# RZT2L register map
Vendor: Renesas Electronics Corporation; Series: RZT; File version: 1.20.00
CPU: other r0p0, little endian, MPU, no FPU, VTOR, 4 interrupt priority bits, 624 interrupts
Registers are 32-bit, read-write, reset 0x0 unless marked. A register's access mark holds for its fields unless they carry their own. Offsets are from the block's base; [hi:lo] are bit positions; {n}, {i} and the like mark numbered series; 'fields as' and 'values as' point back to an identical list.

## GMAC — Ethernet MAC
Base 0x80100000
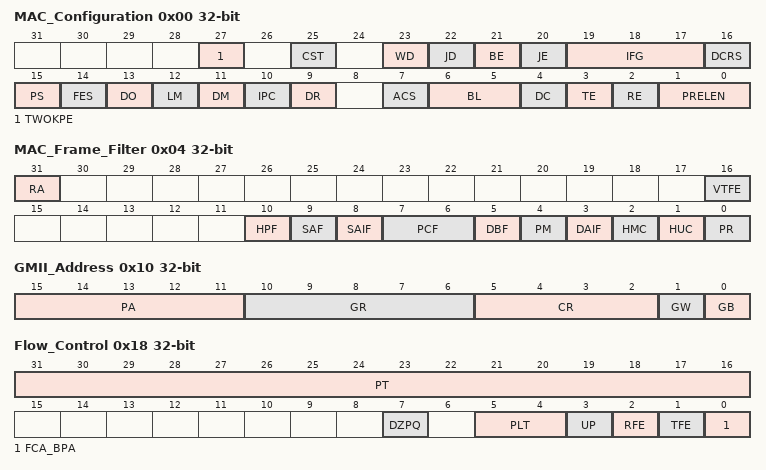
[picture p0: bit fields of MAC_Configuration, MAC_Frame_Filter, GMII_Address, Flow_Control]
0x00 MAC_Configuration
  [27] TWOKPE — IEEE 802.3 as Support for 2 K Packets
  [25] CST — CRC Stripping for Type Frames
  [23] WD — Watchdog Disable
  [22] JD — Jabber Disable
  [21] BE — Frame Burst Enable
  [20] JE — Jumbo Frame Enable
  [19:17] IFG — Inter-Frame Gap
  [16] DCRS — Disable Carrier Sense During Transmission
  [15] PS — Port Select
    0=For 1000 Mbps operations; 1=For 10 or 100 Mbps operations
  [14] FES — Speed
    0=10 Mbps; 1=100 Mbps
  [13] DO — Disable Receive Own
  [12] LM — Loopback Mode
  [11] DM — Duplex Mode
  [10] IPC — Checksum Offload
  [9] DR — Disable Retry
  [7] ACS — Automatic Pad or CRC Stripping
  [6:5] BL — Back-Off Limit
    0=k = min (n, 10); 1=k = min (n, 8); 2=k = min (n, 4); 3=k = min (n, 1)
  [4] DC — Deferral Check
  [3] TE — Transmitter Enable
  [2] RE — Receiver Enable
  [1:0] PRELEN — Preamble Length for Transmit Frames
    0=7 bytes of preamble; 1=5 bytes of preamble; 2=3 bytes of preamble
0x04 MAC_Frame_Filter
  [31] RA — Receive All
  [16] VTFE — VLAN Tag Filter Enable
  [10] HPF — Hash or Perfect Filter
  [9] SAF — Source Address Filter Enable
  [8] SAIF — SA Inverse Filtering
  [7:6] PCF — Pass Control Frames
    0=GMAC filters all control frames from reaching the application; 1=GMAC forwards all control frames except PAUSE control frames to application even if they fail the Address filter; 2=GMAC forwards all control frames to application even if they fail the Address Filter; 3=GMAC forwards control frames that pass the Address Filter
  [5] DBF — Disable Broadcast Frames
  [4] PM — Pass All Multicast
  [3] DAIF — DA Inverse Filtering
  [2] HMC — Hash Multicast
  [1] HUC — Hash Unicast
  [0] PR — Promiscuous Mode
0x10 GMII_Address
  [15:11] PA — Physical Layer Address
  [10:6] GR — GMII Register
  [5:2] CR — CSR Clock Range
    0=The frequency of the CSR clock is 60-100 MHz, and the MDC clock is CSR clock/42; 1=The frequency of the CSR clock is 100-150 MHz, and the MDC clock is CSR clock/62; 2=The frequency of the CSR clock is 20-35 MHz, and the MDC clock is CSR clock/16; 3=The frequency of the CSR clock is 35-60 MHz, and the MDC clock is CSR clock/26; 4=The frequency of the CSR clock is 150-250 MHz, and the MDC clock is CSR clock/102; 5=The frequency of the CSR clock is 250-300 MHz, and the MDC clock is CSR clock/124
  [1] GW — GMII Write
  [0] GB — GMII Busy
0x14 GMII_Data (reset mask 0xFE00)
  [15:0] GD — GMII Data
0x18 Flow_Control
  [31:16] PT — Pause Time
  [7] DZPQ — Disable Zero-Quanta Pause
  [5:4] PLT — Pause Low Threshold
    0=The threshold is Pause time minus 4 slot times (PT - 4 slot times); 1=The threshold is Pause time minus 28 slot times (PT - 28 slot times); 2=The threshold is Pause time minus 144 slot times (PT - 144 slot times); 3=The threshold is Pause time minus 256 slot times (PT - 256 slot times)
  [3] UP — Unicast Pause Frame Detect
  [2] RFE — Receive Flow Control Enable
  [1] TFE — Transmit Flow Control Enable
  [0] FCA_BPA — Flow Control Busy or Backpressure Activate
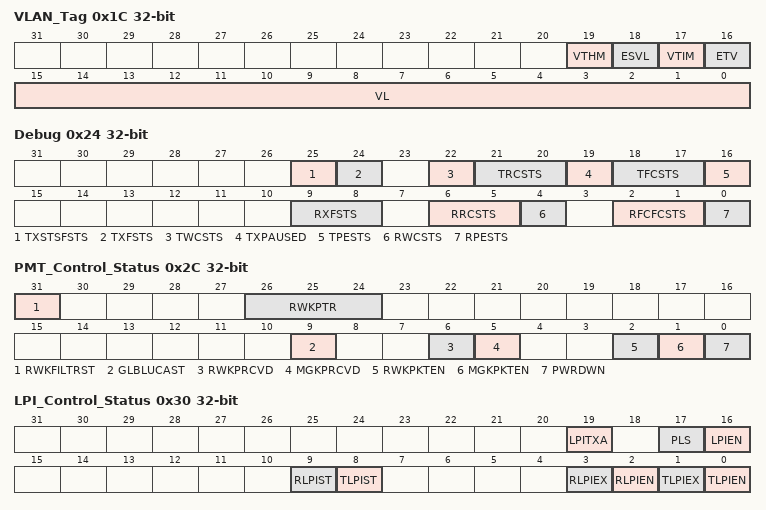
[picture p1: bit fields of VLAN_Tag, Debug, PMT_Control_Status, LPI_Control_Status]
0x1C VLAN_Tag
  [19] VTHM — VLAN Tag Hash Table Match Enable
  [18] ESVL — Enable S-VLAN
  [17] VTIM — VLAN Tag Inverse Match Enable
  [16] ETV — Enable 12-Bit VLAN Tag Comparison
  [15:0] VL — VLAN Tag Identifier for Receive Frames
0x20 Version ro reset 0x3137
  [15:0] VER — Version (GMAC: 0x3137)
0x24 Debug ro
  [25] TXSTSFSTS — MTL TX Status FIFO Full Status
  [24] TXFSTS — MTL TX FIFO Not Empty Status
  [22] TWCSTS — MTL TX FIFO Write Controller Active Status
  [21:20] TRCSTS — MTL TX FIFO Read Controller Status
    0=IDLE state; 1=READ state (transferring data to GMAC transmitter); 2=Waiting for TX status from GMAC transmitter; 3=Writing the received TX status or flushing the TX FIFO
  [19] TXPAUSED — GMAC transmitter in PAUSE
  [18:17] TFCSTS — GMAC Transmit Frame Controller Status
    0=IDLE state; 1=Waiting for status of previous frame, or IFG, or backoff period to be over; 2=Generating and transmitting a Pause control frame (in the full-duplex mode); 3=Transferring input frame for transmission
  [16] TPESTS — GMAC GMII or MII Transmit Protocol Engine Status
  [9:8] RXFSTS — MTL RX FIFO Fill-level Status
    0=RX FIFO Empty; 1=RX FIFO fill level is below the flow-control deactivate threshold; 2=RX FIFO fill level is above the flow-control activate threshold; 3=RX FIFO Full
  [6:5] RRCSTS — MTL RX FIFO Read Controller State
    0=IDLE state; 1=Reading frame data; 2=Reading frame status (or timestamp); 3=Flushing the frame data and status
  [4] RWCSTS — MTL RX FIFO Write Controller Active Status
  [2:1] RFCFCSTS — GMAC Receive Frame Controller FIFO Status
  [0] RPESTS — GMAC GMII or MII Receive Protocol Engine Status
0x28 Remote_Wake_Up_Frame_Filter
  [31:0] WKUPFRMFTR — Remote Wake-Up Frame Filter
0x2C PMT_Control_Status — PMT Control and Status Register
  [31] RWKFILTRST — Wake-Up Frame Filter Register Pointer Reset
  [26:24] RWKPTR ro — Remote Wake-Up FIFO Pointer
  [9] GLBLUCAST — Global Unicast
  [6] RWKPRCVD ro — Wake-Up Frame Received
  [5] MGKPRCVD ro — Magic Packet Received
  [2] RWKPKTEN — Wake-Up Frame Enable
  [1] MGKPKTEN — Magic Packet Enable
  [0] PWRDWN — Power Down
0x30 LPI_Control_Status — LPI Control and Status Register
  [19] LPITXA — LPI TX Automate
  [17] PLS — PHY Link Status
  [16] LPIEN — LPI Enable
  [9] RLPIST ro — Receive LPI State
  [8] TLPIST ro — Transmit LPI State
  [3] RLPIEX ro — Receive LPI Exit
  [2] RLPIEN ro — Receive LPI Entry
  [1] TLPIEX ro — Transmit LPI Exit
  [0] TLPIEN ro — Transmit LPI Entry
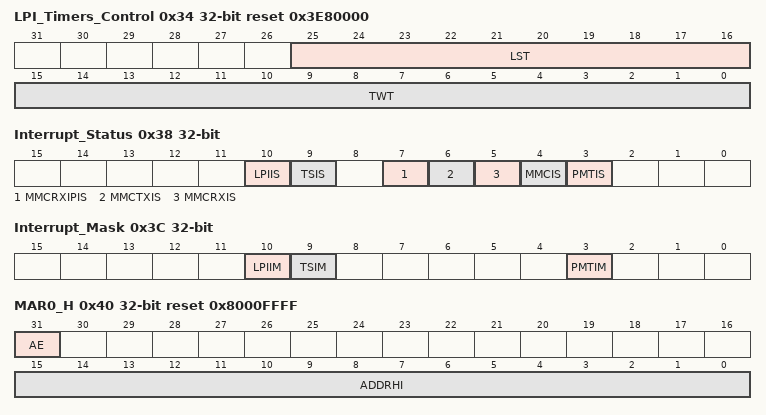
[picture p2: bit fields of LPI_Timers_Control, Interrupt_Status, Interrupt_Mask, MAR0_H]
0x34 LPI_Timers_Control reset 0x3E80000
  [25:16] LST — LPI LS Timer
  [15:0] TWT — LPI TW Timer
0x38 Interrupt_Status ro
  [10] LPIIS — LPI Interrupt Status
  [9] TSIS — Timestamp Interrupt Status
  [7] MMCRXIPIS — MMC Receive Checksum Offload Interrupt Status
  [6] MMCTXIS — MMC Transmit Interrupt Status
  [5] MMCRXIS — MMC Receive Interrupt Status
  [4] MMCIS — MMC Interrupt Status
  [3] PMTIS — PMT Interrupt Status
0x3C Interrupt_Mask reset not defined
  [10] LPIIM — LPI Interrupt Mask
  [9] TSIM — Timestamp Interrupt Mask
  [3] PMTIM — PMT Interrupt Mask
0x40 MAR0_H reset 0x8000FFFF — MAC Address 0 High Register
  [31] AE ro — Address Enable
  [15:0] ADDRHI — MAC Address0[47:32]
0x44 MAR0_L reset 0xFFFFFFFF — MAC Address 0 Low Register
  [31:0] ADDRLO — MAC Address0[31:0]
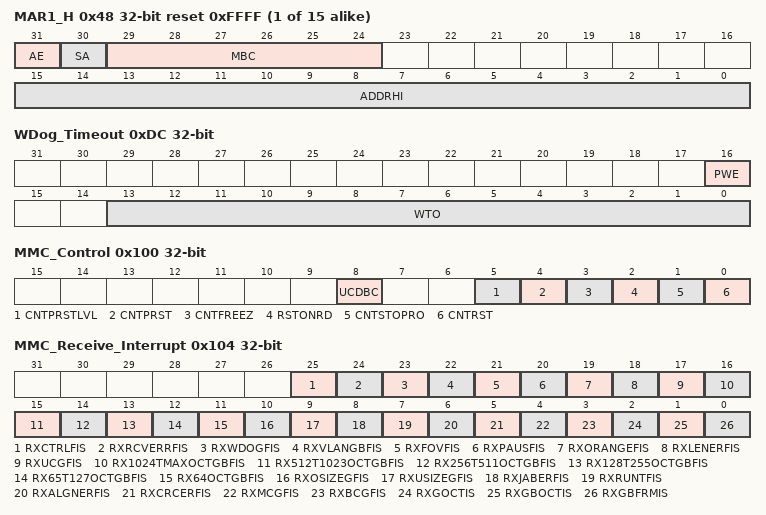
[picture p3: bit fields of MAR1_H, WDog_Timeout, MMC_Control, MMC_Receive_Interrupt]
{0x40+8i} MAR{i}_H (i=1..15) reset 0xFFFF — MAC ADDRESS High Register
  [31] AE — Address Enable
  [30] SA — Source Address
  [29:24] MBC — Mask Byte Control
  [15:0] ADDRHI — MAC Address n[47:32]
{0x44+8i} MAR{i}_L (i=1..15) reset 0xFFFFFFFF — MAC ADDRESS Low Register
  [31:0] ADDRLO — MAC Address n[31:0]
0xDC WDog_Timeout — Watchdog Timeout Register
  [16] PWE — Programmable Watchdog Enable
  [13:0] WTO — Watchdog Timeout
0x100 MMC_Control
  [8] UCDBC — Update MMC Counters for Dropped Broadcast Frames
  [5] CNTPRSTLVL — Full-Half Preset
  [4] CNTPRST — Counters Preset
  [3] CNTFREEZ — MMC Counter Freeze
  [2] RSTONRD — Reset on Read
  [1] CNTSTOPRO — Counters Stop Rollover
  [0] CNTRST — Counters Reset
0x104 MMC_Receive_Interrupt ro
  [25] RXCTRLFIS — MMC Receive Control Frame Counter Interrupt Status
  [24] RXRCVERRFIS — MMC Receive Error Frame Counter Interrupt Status
  [23] RXWDOGFIS — MMC Receive Watchdog Error Frame Counter Interrupt Status
  [22] RXVLANGBFIS — MMC Receive VLAN Good Bad Frame Counter Interrupt Status
  [21] RXFOVFIS — MMC Receive FIFO Overflow Frame Counter Interrupt Status
  [20] RXPAUSFIS — MMC Receive Pause Frame Counter Interrupt Status
  [19] RXORANGEFIS — MMC Receive Out Of Range Error Frame Counter Interrupt Status
  [18] RXLENERFIS — MMC Receive Length Error Frame Counter Interrupt Status
  [17] RXUCGFIS — MMC Receive Unicast Good Frame Counter Interrupt Status
  [16] RX1024TMAXOCTGBFIS — MMC Receive 1024 to Maximum Octet Good Bad Frame Counter Interrupt Status
  [15] RX512T1023OCTGBFIS — MMC Receive 512 to 1023 Octet Good Bad Frame Counter Interrupt Status
  [14] RX256T511OCTGBFIS — MMC Receive 256 to 511 Octet Good Bad Frame Counter Interrupt Status
  [13] RX128T255OCTGBFIS — MMC Receive 128 to 255 Octet Good Bad Frame Counter Interrupt Status
  [12] RX65T127OCTGBFIS — MMC Receive 65 to 127 Octet Good Bad Frame Counter Interrupt Status
  [11] RX64OCTGBFIS — MMC Receive 64 Octet Good Bad Frame Counter Interrupt Status
  [10] RXOSIZEGFIS — MMC Receive Oversize Good Frame Counter Interrupt Status
  [9] RXUSIZEGFIS — MMC Receive Undersize Good Frame Counter Interrupt Status
  [8] RXJABERFIS — MMC Receive Jabber Error Frame Counter Interrupt Status
  [7] RXRUNTFIS — MMC Receive Runt Frame Counter Interrupt Status
  [6] RXALGNERFIS — MMC Receive Alignment Error Frame Counter Interrupt Status
  [5] RXCRCERFIS — MMC Receive CRC Error Frame Counter Interrupt Status
  [4] RXMCGFIS — MMC Receive Multicast Good Frame Counter Interrupt Status
  [3] RXBCGFIS — MMC Receive Broadcast Good Frame Counter Interrupt Status
  [2] RXGOCTIS — MMC Receive Good Octet Counter Interrupt Status
  [1] RXGBOCTIS — MMC Receive Good Bad Octet Counter Interrupt Status
  [0] RXGBFRMIS — MMC Receive Good Bad Frame Counter Interrupt Status
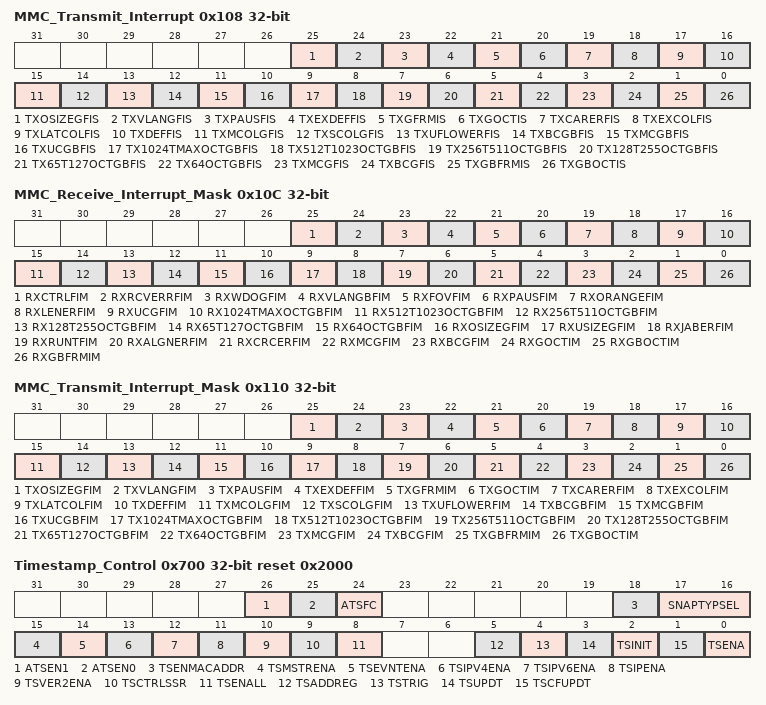
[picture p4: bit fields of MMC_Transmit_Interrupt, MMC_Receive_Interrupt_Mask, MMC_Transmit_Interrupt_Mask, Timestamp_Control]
0x108 MMC_Transmit_Interrupt ro
  [25] TXOSIZEGFIS — MMC Transmit Oversize Good Frame Counter Interrupt Status
  [24] TXVLANGFIS — MMC Transmit VLAN Good Frame Counter Interrupt Status
  [23] TXPAUSFIS — MMC Transmit Pause Frame Counter Interrupt Status
  [22] TXEXDEFFIS — MMC Transmit Excessive Deferral Frame Counter Interrupt Status
  [21] TXGFRMIS — MMC Transmit Good Frame Counter Interrupt Status
  [20] TXGOCTIS — MMC Transmit Good Octet Counter Interrupt Status
  [19] TXCARERFIS — MMC Transmit Carrier Error Frame Counter Interrupt Status
  [18] TXEXCOLFIS — MMC Transmit Excessive Collision Frame Counter Interrupt Status
  [17] TXLATCOLFIS — MMC Transmit Late Collision Frame Counter Interrupt Status
  [16] TXDEFFIS — MMC Transmit Deferred Frame Counter Interrupt Status
  [15] TXMCOLGFIS — MMC Transmit Multiple Collision Good Frame Counter Interrupt Status
  [14] TXSCOLGFIS — MMC Transmit Single Collision Good Frame Counter Interrupt Status
  [13] TXUFLOWERFIS — MMC Transmit Underflow Error Frame Counter Interrupt Status
  [12] TXBCGBFIS — MMC Transmit Broadcast Good Bad Frame Counter Interrupt Status
  [11] TXMCGBFIS — MMC Transmit Multicast Good Bad Frame Counter Interrupt Status
  [10] TXUCGBFIS — MMC Transmit Unicast Good Bad Frame Counter Interrupt Status
  [9] TX1024TMAXOCTGBFIS — MMC Transmit 1024 to Maximum Octet Good Bad Frame Counter Interrupt Status
  [8] TX512T1023OCTGBFIS — MMC Transmit 512 to 1023 Octet Good Bad Frame Counter Interrupt Status
  [7] TX256T511OCTGBFIS — MMC Transmit 256 to 511 Octet Good Bad Frame Counter Interrupt Status
  [6] TX128T255OCTGBFIS — MMC Transmit 128 to 255 Octet Good Bad Frame Counter Interrupt Status
  [5] TX65T127OCTGBFIS — MMC Transmit 65 to 127 Octet Good Bad Frame Counter Interrupt Status
  [4] TX64OCTGBFIS — MMC Transmit 64 Octet Good Bad Frame Counter Interrupt Status
  [3] TXMCGFIS — MMC Transmit Multicast Good Frame Counter Interrupt Status
  [2] TXBCGFIS — MMC Transmit Broadcast Good Frame Counter Interrupt Status
  [1] TXGBFRMIS — MMC Transmit Good Bad Frame Counter Interrupt Status
  [0] TXGBOCTIS — MMC Transmit Good Bad Octet Counter Interrupt Status
0x10C MMC_Receive_Interrupt_Mask
  [25] RXCTRLFIM — MMC Receive Control Frame Counter Interrupt Mask
  [24] RXRCVERRFIM — MMC Receive Error Frame Counter Interrupt Mask
  [23] RXWDOGFIM — MMC Receive Watchdog Error Frame Counter Interrupt Mask
  [22] RXVLANGBFIM — MMC Receive VLAN Good Bad Frame Counter Interrupt Mask
  [21] RXFOVFIM — MMC Receive FIFO Overflow Frame Counter Interrupt Mask
  [20] RXPAUSFIM — MMC Receive Pause Frame Counter Interrupt Mask
  [19] RXORANGEFIM — MMC Receive Out Of Range Error Frame Counter Interrupt Mask
  [18] RXLENERFIM — MMC Receive Length Error Frame Counter Interrupt Mask
  [17] RXUCGFIM — MMC Receive Unicast Good Frame Counter Interrupt Mask
  [16] RX1024TMAXOCTGBFIM — MMC Receive 1024 to Maximum Octet Good Bad Frame Counter Interrupt Mask
  [15] RX512T1023OCTGBFIM — MMC Receive 512 to 1023 Octet Good Bad Frame Counter Interrupt Mask
  [14] RX256T511OCTGBFIM — MMC Receive 256 to 511 Octet Good Bad Frame Counter Interrupt Mask
  [13] RX128T255OCTGBFIM — MMC Receive 128 to 255 Octet Good Bad Frame Counter Interrupt Mask
  [12] RX65T127OCTGBFIM — MMC Receive 65 to 127 Octet Good Bad Frame Counter Interrupt Mask
  [11] RX64OCTGBFIM — MMC Receive 64 Octet Good Bad Frame Counter Interrupt Mask
  [10] RXOSIZEGFIM — MMC Receive Oversize Good Frame Counter Interrupt Mask
  [9] RXUSIZEGFIM — MMC Receive Undersize Good Frame Counter Interrupt Mask
  [8] RXJABERFIM — MMC Receive Jabber Error Frame Counter Interrupt Mask
  [7] RXRUNTFIM — MMC Receive Runt Frame Counter Interrupt Mask
  [6] RXALGNERFIM — MMC Receive Alignment Error Frame Counter Interrupt Mask
  [5] RXCRCERFIM — MMC Receive CRC Error Frame Counter Interrupt Mask
  [4] RXMCGFIM — MMC Receive Multicast Good Frame Counter Interrupt Mask
  [3] RXBCGFIM — MMC Receive Broadcast Good Frame Counter Interrupt Mask
  [2] RXGOCTIM — MMC Receive Good Octet Counter Interrupt Mask
  [1] RXGBOCTIM — MMC Receive Good Bad Octet Counter Interrupt Mask
  [0] RXGBFRMIM — MMC Receive Good Bad Frame Counter Interrupt Mask
0x110 MMC_Transmit_Interrupt_Mask
  [25] TXOSIZEGFIM — MMC Transmit Oversize Good Frame Counter Interrupt Mask
  [24] TXVLANGFIM — MMC Transmit VLAN Good Frame Counter Interrupt Mask
  [23] TXPAUSFIM — MMC Transmit Pause Frame Counter Interrupt Mask
  [22] TXEXDEFFIM — MMC Transmit Excessive Deferral Frame Counter Interrupt Mask
  [21] TXGFRMIM — MMC Transmit Good Frame Counter Interrupt Mask
  [20] TXGOCTIM — MMC Transmit Good Octet Counter Interrupt Mask
  [19] TXCARERFIM — MMC Transmit Carrier Error Frame Counter Interrupt Mask
  [18] TXEXCOLFIM — MMC Transmit Excessive Collision Frame Counter Interrupt Mask
  [17] TXLATCOLFIM — MMC Transmit Late Collision Frame Counter Interrupt Mask
  [16] TXDEFFIM — MMC Transmit Deferred Frame Counter Interrupt Mask
  [15] TXMCOLGFIM — MMC Transmit Multiple Collision Good Frame Counter Interrupt Mask
  [14] TXSCOLGFIM — MMC Transmit Single Collision Good Frame Counter Interrupt Mask
  [13] TXUFLOWERFIM — MMC Transmit Underflow Error Frame Counter Interrupt Mask
  [12] TXBCGBFIM — MMC Transmit Broadcast Good Bad Frame Counter Interrupt Mask
  [11] TXMCGBFIM — MMC Transmit Multicast Good Bad Frame Counter Interrupt Mask
  [10] TXUCGBFIM — MMC Transmit Unicast Good Bad Frame Counter Interrupt Mask
  [9] TX1024TMAXOCTGBFIM — MMC Transmit 1024 to Maximum Octet Good Bad Frame Counter Interrupt Mask
  [8] TX512T1023OCTGBFIM — MMC Transmit 512 to 1023 Octet Good Bad Frame Counter Interrupt Mask
  [7] TX256T511OCTGBFIM — MMC Transmit 256 to 511 Octet Good Bad Frame Counter Interrupt Mask
  [6] TX128T255OCTGBFIM — MMC Transmit 128 to 255 Octet Good Bad Frame Counter Interrupt Mask
  [5] TX65T127OCTGBFIM — MMC Transmit 65 to 127 Octet Good Bad Frame Counter Interrupt Mask
  [4] TX64OCTGBFIM — MMC Transmit 64 Octet Good Bad Frame Counter Interrupt Mask
  [3] TXMCGFIM — MMC Transmit Multicast Good Frame Counter Interrupt Mask
  [2] TXBCGFIM — MMC Transmit Broadcast Good Frame Counter Interrupt Mask
  [1] TXGBFRMIM — MMC Transmit Good Bad Frame Counter Interrupt Mask
  [0] TXGBOCTIM — MMC Transmit Good Bad Octet Counter Interrupt Mask
0x114 Tx_Octet_Count_Good_Bad ro — Transmit Octet Count for Good and Bad Frames
  [31:0] TXOCTGB — This field indicates the number of bytes transmitted in good and bad frames exclusive of preamble and retried bytes.
0x118 Tx_Frame_Count_Good_Bad ro — Transmit Frame Count for Good and Bad Frames
  [31:0] TXFRMGB — This field indicates the number of good and bad frames transmitted, exclusive of retried frames.
0x11C Tx_Broadcast_Frames_Good ro — Transmit Frame Count for Good Broadcast Frames
  [31:0] TXBCASTG — This field indicates the number of transmitted good broadcast frames.
0x120 Tx_Multicast_Frames_Good ro — Transmit Frame Count for Good Multicast Frames
  [31:0] TXMCASTG — This field indicates the number of transmitted good multicast frames.
0x124 Tx_64Octets_Frames_Good_Bad ro — Transmit Octet Count for Good and Bad 64 Byte Frames
  [31:0] TX64OCTGB — This field indicates the number of transmitted good and bad frames with length of 64 bytes, exclusive of preamble and retried frames.
0x128 Tx_65To127Octets_Frames_Good_Bad ro — Transmit Octet Count for Good and Bad 65 to 127 Bytes Frames
  [31:0] TX65_127OCTGB — This field indicates the number of transmitted good and bad frames with length between 65 and 127 (inclusive) bytes, exclusive of preamble and retried frames.
0x12C Tx_128To255Octets_Frames_Good_Bad ro — Transmit Octet Count for Good and Bad 128 to 255 Bytes Frames
  [31:0] TX128_255OCTGB — This field indicates the number of transmitted good and bad frames with length between 128 and 255 (inclusive) bytes, exclusive of preamble and retried frames.
0x130 Tx_256To511Octets_Frames_Good_Bad ro — Transmit Octet Count for Good and Bad 256 to 511 Bytes Frames
  [31:0] TX256_511OCTGB — This field indicates the number of transmitted good and bad frames with length between 256 and 511 (inclusive) bytes, exclusive of preamble and retried frames.
0x134 Tx_512To1023Octets_Frames_Good_Bad ro — Transmit Octet Count for Good and Bad 512 to 1023 Bytes Frames
  [31:0] TX512_1023OCTGB — This field indicates the number of transmitted good and bad frames with length between 512 and 1,023 (inclusive) bytes, exclusive of preamble and retried frames.
0x138 Tx_1024ToMaxOctets_Frames_Good_Bad ro — Transmit Octet Count for Good and Bad 1024 to Maxsize Bytes Frames
  [31:0] TX1024_MAXOCTGB — This field indicates the number of good and bad frames transmitted with length between 1,024 and maxsize (inclusive) bytes, exclusive of preamble and retried frames.
0x13C Tx_Unicast_Frames_Good_Bad ro — Transmit Frame Count for Good and Bad Unicast Frames
  [31:0] TXUCASTGB — This field indicates the number of transmitted good and bad unicast frames.
0x140 Tx_Multicast_Frames_Good_Bad ro — Transmit Frame Count for Good and Bad Multicast Frames
  [31:0] TXMCASTGB — This field indicates the number of transmitted good and bad multicast frames.
0x144 Tx_Broadcast_Frames_Good_Bad ro — Transmit Frame Count for Good and Bad Broadcast Frames
  [31:0] TXBCASTGB — This field indicates the number of transmitted good and bad broadcast frames.
0x148 Tx_Underflow_Error_Frames ro — Transmit Frame Count for Underflow Error Frames
  [15:0] TXUNDRFLW — This field indicates the number of frames aborted because of frame underflow error.
0x14C Tx_Single_Collision_Good_Frames ro — Transmit Frame Count for Frames Transmitted after Single Collision
  [15:0] TXSNGLCOLG — This field indicates the number of successfully transmitted frames after a single collision in the half-duplex mode.
0x150 Tx_Multiple_Collision_Good_Frames ro — Transmit Frame Count for Frames Transmitted after Multiple Collision
  [15:0] TXMULTCOLG — This field indicates the number of successfully transmitted frames after multiple collisions in the half-duplex mode.
0x154 Tx_Deferred_Frames ro — Transmit Frame Count for Deferred Frames
  [15:0] TXDEFRD — This field indicates the number of successfully transmitted frames after a deferral in the half-duplex mode.
0x158 Tx_Late_Collision_Frames ro — Transmit Frame Count for Late Collision Error Frames
  [15:0] TXLATECOL — This field indicates the number of frames aborted because of late collision error.
0x15C Tx_Excessive_Collision_Frames ro — Transmit Frame Count for Excessive Collision Error Frames
  [15:0] TXEXSCOL — This field indicates the number of frames aborted because of excessive (16) collision error.
0x160 Tx_Carrier_Error_Frames ro — Transmit Frame Count for Carrier Sense Error Frames
  [15:0] TXCARR — This field indicates the number of frames aborted because of carrier sense error (no carrier or loss of carrier).
0x164 Tx_Octet_Count_Good ro — Transmit Octet Count for Good Frames
  [31:0] TXOCTG
0x168 Tx_Frame_Count_Good ro — Transmit Frame Count for Good Frames
  [31:0] TXFRMG — This field indicates the number of transmitted good frames, exclusive of preamble.
0x16C Tx_Excessive_Deferral_Error ro — Transmit Frame Count for Excessive Deferral Error Frames
  [15:0] TXEXSDEF — This field indicates the number of frames aborted because of excessive deferral error, that is, frames deferred for more than two max sized frame times.
0x170 Tx_Pause_Frames ro — Transmit Frame Count for Good PAUSE Frames
  [15:0] TXPAUSE — This field indicates the number of transmitted good PAUSE frames.
0x174 Tx_VLAN_Frames_Good ro — Transmit Frame Count for Good VLAN Frames
  [31:0] TXVLANG — This register maintains the number of transmitted good VLAN frames, exclusive of retried frames.
0x178 Tx_OSize_Frames_Good ro — Transmit Frame Count for Good Oversize Frames
  [15:0] TXOSIZG — This field indicates the number of frames transmitted without errors and with length greater than the maxsize (1,518 or 1,522 bytes for VLAN tagged frames; 2000 bytes if enabled in bit [27] of MAC Configuration Register (MAC_Configuration)).
0x180 Rx_Frames_Count_Good_Bad ro — Receive Frame Count for Good and Bad Frames
  [31:0] RXFRMGB — This field indicates the number of received good and bad frames.
0x184 Rx_Octet_Count_Good_Bad ro — Receive Octet Count for Good and Bad Frames
  [31:0] RXOCTGB — This field indicates the number of bytes received, exclusive of preamble, in good and bad frames.
0x188 Rx_Octet_Count_Good ro — Receive Octet Count for Good Frames
  [31:0] RXOCTG — This field indicates the number of bytes received, exclusive of preamble, only in good frames.
0x18C Rx_Broadcast_Frames_Good ro — Receive Frame Count for Good Broadcast Frames
  [31:0] RXBCASTG — This field indicates the number of received good broadcast frames.
0x190 Rx_Multicast_Frames_Good ro — Receive Frame Count for Good Multicast Frames
  [31:0] RXMCASTG — This field indicates the number of received good multicast frames.
0x194 Rx_CRC_Error_Frames ro — Receive Frame Count for CRC Error Frames
  [15:0] RXCRCERR — This field indicates the number of frames received with CRC error.
0x198 Rx_Alignment_Error_Frames ro — Receive Frame Count for Alignment Error Frames
  [15:0] RXALGNERR — This field indicates the number of frames received with alignment (dribble) error. This field is valid only in the 10 or 100 Mbps mode.
0x19C Rx_Runt_Error_Frames ro — Receive Frame Count for Runt Error Frames
  [15:0] RXRUNTERR — This field indicates the number of frames received with runt error (< 64 bytes and CRC error).
0x1A0 Rx_Jabber_Error_Frames ro — Receive Frame Count for Jabber Error Frames
  [15:0] RXJABERR — This field indicates the number of giant frames received with length (including CRC) greater than 1,518 bytes (1,522 bytes for VLAN tagged) and with CRC error. If Jumbo Frame mode is enabled, then frames of length greater than 9,018 bytes (9,022 for VLAN tagged) are considered as giant frames.
0x1A4 Rx_Undersize_Frames_Good ro — Receive Frame Count for Undersize Frames
  [15:0] RXUNDERSZG — This field indicates the number of frames received with length less than 64 bytes and without errors.
0x1A8 Rx_Oversize_Frames_Good ro — Receive Frame Count for Oversize Frames
  [15:0] RXOVERSZG — This field indicates the number of frames received without errors, with length greater than the maxsize (1,518 or 1,522 for VLAN tagged frames; 2,000 bytes if enabled in bit [27] of MAC Configuration Register (MAC_Configuration)).
0x1AC Rx_64Octets_Frames_Good_Bad ro — Receive Frame Count for Good and Bad 64 Byte Frames
  [31:0] RX64OCTGB — This field indicates the number of received good and bad frames with length 64 bytes, exclusive of preamble.
0x1B0 Rx_65To127Octets_Frames_Good_Bad ro — Receive Frame Count for Good and Bad 65 to 127 Bytes Frames
  [31:0] RX65_127OCTGB — This field indicates the number of received good and bad frames received with length between 65 and 127 (inclusive) bytes, exclusive of preamble.
0x1B4 Rx_128To255Octets_Frames_Good_Bad ro — Receive Frame Count for Good and Bad 128 to 255 Bytes Frames
  [31:0] RX128_255OCTGB — This field indicates the number of received good and bad frames with length between 128 and 255 (inclusive) bytes, exclusive of preamble.
0x1B8 Rx_256To511Octets_Frames_Good_Bad ro — Receive Frame Count for Good and Bad 256 to 511 Bytes Frames
  [31:0] RX256_511OCTGB — This field indicates the number of received good and bad frames with length between 256 and 511 (inclusive) bytes, exclusive of preamble.
0x1BC Rx_512To1023Octets_Frames_Good_Bad ro — Receive Frame Count for Good and Bad 512 to 1,023 Bytes Frames
  [31:0] RX512_1023OCTGB — This field indicates the number of received good and bad frames with length between 512 and 1,023 (inclusive) bytes, exclusive of preamble.
0x1C0 Rx_1024ToMaxOctets_Frames_Good_Bad ro — Receive Frame Count for Good and Bad 1,024 to Maxsize Bytes Frames
  [31:0] RX1024_MAXOCTGB — This field indicates the number of received good and bad frames with length between 1,024 and maxsize (inclusive) bytes, exclusive of preamble and retried frames.
0x1C4 Rx_Unicast_Frames_Good ro — Receive Frame Count for Good Unicast Frames
  [31:0] RXUCASTG — This field indicates the number of received good unicast frames.
0x1C8 Rx_Length_Error_Frames ro — Receive Frame Count for Length Error Frames
  [15:0] RXLENERR
0x1CC Rx_Out_Of_Range_Type_Frames ro — Receive Frame Count for Out of Range Frames
  [15:0] RXOUTOFRNG — This field indicates the number of received frames with length field not equal to the valid frame size (greater than 1,500 but less than 1,536).
0x1D0 Rx_Pause_Frames ro — Receive Frame Count for PAUSE Frames
  [15:0] RXPAUSEFRM — This field indicates the number of received good and valid PAUSE frames.
0x1D4 Rx_FIFO_Overflow_Frames ro — Receive Frame Count for FIFO Overflow Frames
  [15:0] RXFIFOOVFL — This field indicates the number of received frames missed because of FIFO overflow.
0x1D8 Rx_VLAN_Frames_Good_Bad ro — Receive Frame Count for Good and Bad VLAN Frames
  [31:0] RXVLANFRGB — This field indicates the number of received good and bad VLAN frames.
0x1DC Rx_Watchdog_Error_Frames ro — Receive Frame Count for Watchdog Error Frames
  [15:0] RXWDGERR — This field indicates the number of frames received with error because of the watchdog timeout error (frames with more than 2,048 bytes or value programmed in Watchdog Timeout Register (WDog_Timeout)).
0x1E0 Rx_Receive_Error_Frames ro — Receive Frame Count for Receive Error Frames
  [15:0] RXRCVERR — This field indicates the number of frames received with error because of the GMII/MII RXER error or Frame Extension error on GMII.
0x1E4 Rx_Control_Frames_Good ro — Receive Frame Count for Good Control Frames
  [31:0] RXCTRLG — This field indicates the number of good control frames received.
0x400 GMACTRGSEL — GMAC PTP Trigger Select Register
  [1:0] TRGSEL — Select PTP Timestamp Trigger for GMAC IP
    0=Select GMAC_PTPTRGn (n = 0, 1) trigger from ELC; 1=Select external GMAC_PTPTRGn (n = 0, 1) trigger input pin
{0x500+4i} HASH_TABLE_REG{i} (i=0..7) — Hash Table Register {i} (n = 0 to 7)
  [31:0] HT — This field contains the nth 32 bits [31:0] of the Hash table.
0x588 VLAN_Hash_Table_Reg — VLAN Hash Table Register
  [15:0] VLHT — VLAN Hash Table
0x700 Timestamp_Control reset 0x2000
  [26] ATSEN1 — Auxiliary Snapshot 1 Enable
  [25] ATSEN0 — Auxiliary Snapshot 0 Enable
  [24] ATSFC — Auxiliary Snapshot FIFO Clear
  [18] TSENMACADDR — Enable MAC address for PTP Frame Filtering
  [17:16] SNAPTYPSEL — Select PTP packets for Taking Snapshots
  [15] TSMSTRENA — Enable Snapshot for Messages Relevant to Master
  [14] TSEVNTENA — Enable Timestamp Snapshot for Event Messages
  [13] TSIPV4ENA — Enable Processing of PTP Frames Sent over IPv4 UDP
  [12] TSIPV6ENA — Enable Processing of PTP Frames Sent Over IPv6 UDP
  [11] TSIPENA — Enable Processing of PTP over Ethernet Frames
  [10] TSVER2ENA — Enable PTP packet Processing for Version 2 Format
  [9] TSCTRLSSR — Timestamp Digital or Binary Rollover Control
  [8] TSENALL — Enable Timestamp for all Frames
  [5] TSADDREG — Addend Reg Update
  [4] TSTRIG — Timestamp Interrupt Trigger Enable
  [3] TSUPDT — Timestamp Update
  [2] TSINIT — Timestamp Initialize
  [1] TSCFUPDT — Timestamp Fine or Coarse Update
  [0] TSENA — Timestamp Enable
0x704 Sub_Second_Increment
  [7:0] SSINC — Sub-second Increment Value
0x708 System_Time_Seconds ro
  [31:0] TSS — Timestamp Second
0x70C System_Time_Nanoseconds ro
  [30:0] TSSS — Timestamp Sub Seconds
0x710 System_Time_Seconds_Update
  [31:0] TSS — Timestamp Second
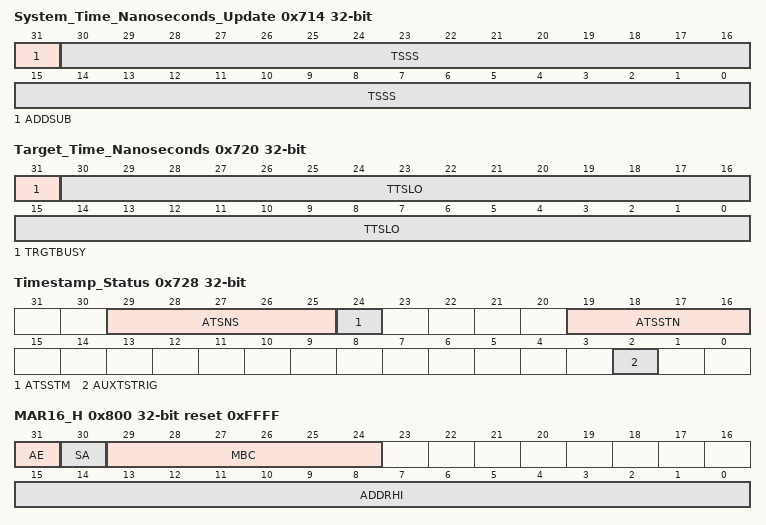
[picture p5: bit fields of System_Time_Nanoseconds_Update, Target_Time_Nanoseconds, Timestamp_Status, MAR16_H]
0x714 System_Time_Nanoseconds_Update
  [31] ADDSUB — Add or subtract time
  [30:0] TSSS — Timestamp Sub Seconds
0x718 Timestamp_Addend
  [31:0] TSAR — Timestamp Addend
0x71C Target_Time_Seconds
  [31:0] TSTR — Target Time Seconds
0x720 Target_Time_Nanoseconds
  [31] TRGTBUSY ro — Target Time Register Busy
  [30:0] TTSLO — Target Timestamp Low Register
0x728 Timestamp_Status ro
  [29:25] ATSNS — Number of Auxiliary Timestamp Snapshots
  [24] ATSSTM — Auxiliary Timestamp Snapshot Trigger Missed
  [19:16] ATSSTN — Auxiliary Timestamp Snapshot Trigger Identifier
  [2] AUXTSTRIG — Auxiliary Timestamp Trigger Snapshot
0x730 Auxiliary_Timestamp_Nanoseconds ro
  [30:0] AUXTSLO — Contains the lower 32 bits (nanoseconds field) of the auxiliary timestamp.
0x734 Auxiliary_Timestamp_Seconds ro
  [31:0] AUXTSHI — Contains the upper 32 bits (Seconds field) of the auxiliary timestamp.
0x800 MAR16_H reset 0xFFFF — MAC ADDRESS High Register
  fields as MAR1_H
0x804 MAR16_L reset 0xFFFFFFFF — MAC ADDRESS Low Register
  [31:0] ADDRLO — MAC Address n[31:0]
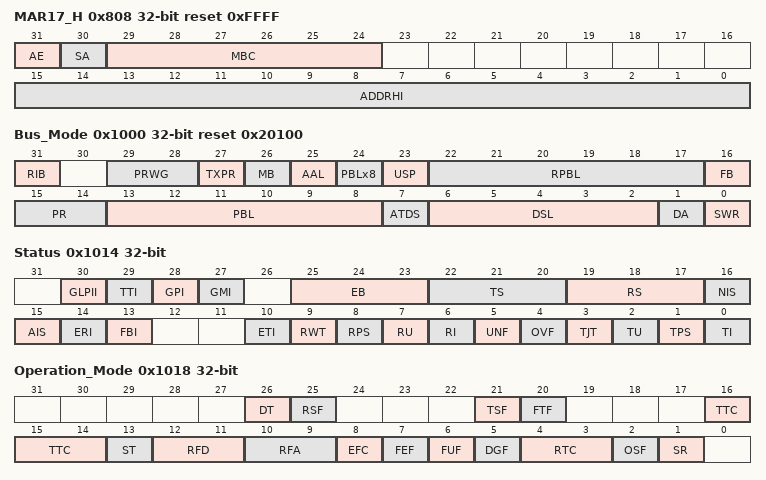
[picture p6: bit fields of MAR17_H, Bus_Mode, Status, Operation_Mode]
0x808 MAR17_H reset 0xFFFF — MAC ADDRESS High Register
  fields as MAR1_H
0x80C MAR17_L reset 0xFFFFFFFF — MAC ADDRESS Low Register
  [31:0] ADDRLO — MAC Address n[31:0]
0x1000 Bus_Mode reset 0x20100
  [31] RIB ro — Rebuild INCRx Burst
  [29:28] PRWG ro — Channel Priority Weights
  [27] TXPR ro — Transmit Priority
  [26] MB ro — Mixed Burst
  [25] AAL — Address Aligned Beats
  [24] PBLx8 — PBLx8 Mode
  [23] USP — Use Separate PBL
  [22:17] RPBL — RX DMA PBL
  [16] FB — Fixed Burst
  [15:14] PR ro — Priority Ratio
  [13:8] PBL — Programmable Burst Length
  [7] ATDS — Enhanced Descriptor Size
  [6:2] DSL — Descriptor Skip Length
  [1] DA ro — DMA Arbitration Scheme
  [0] SWR — Software Reset
0x1004 Transmit_Poll_Demand
  [31:0] TPD — Transmit Poll Demand
0x1008 Receive_Poll_Demand
  [31:0] RPD — Receive Poll Demand
0x100C Receive_Descriptor_List_Address
  [31:2] RDESLA_32bit — Start of Receive List
0x1010 Transmit_Descriptor_List_Address
  [31:2] TDESLA_32bit — Start of Transmit List
0x1014 Status
  [30] GLPII ro — GMAC LPI Interrupt
  [29] TTI ro — Timestamp Trigger Interrupt
  [28] GPI ro — GMAC PMT Interrupt
  [27] GMI ro — GMAC MMC Interrupt
  [25:23] EB ro — Error Bits
    0=Error during RX DMA Write Data Transfer; 3=Error during TX DMA Read Data Transfer; 4=Error during RX DMA Descriptor Write Access; 5=Error during TX DMA Descriptor Write Access; 6=Error during RX DMA Descriptor Read Access; 7=Error during TX DMA Descriptor Read Access
  [22:20] TS ro — Transmit Process State
    0=Stopped: Reset or Stop Transmit Command issued; 1=Running: Fetching Transmit Transfer Descriptor; 2=Running: Waiting for status; 3=Running: Reading Data from host memory buffer and queuing it to transmit buffer (Tx FIFO); 4=TIME_STAMP write state; 5=Reserved for future use; 6=Suspended: Transmit Descriptor Unavailable or Transmit Buffer Underflow; 7=Running: Closing Transmit Descriptor
  [19:17] RS ro — Received Process State
    0=Stopped: Reset or Stop Receive Command issued; 1=Running: Fetching Receive Transfer Descriptor; 2=Reserved for future use; 3=Running: Waiting for receive packet; 4=Suspended: Receive Descriptor Unavailable; 5=Running: Closing Receive Descriptor; 6=TIME_STAMP write state; 7=Running: Transferring the receive packet data from receive buffer to host memory
  [16] NIS — Normal Interrupt Summary
  [15] AIS — Abnormal Interrupt Summary
  [14] ERI — Early Receive Interrupt
  [13] FBI — Fatal Bus Error Interrupt
  [10] ETI — Early Transmit Interrupt
  [9] RWT — Receive Watchdog Timeout
  [8] RPS — Receive Process Stopped
  [7] RU — Receive Buffer Unavailable
  [6] RI — Receive Interrupt
  [5] UNF — Transmit Underflow
  [4] OVF — Receive Overflow
  [3] TJT — Transmit Jabber Timeout
  [2] TU — Transmit Buffer Unavailable
  [1] TPS — Transmit Process Stopped
  [0] TI — Transmit Interrupt
0x1018 Operation_Mode
  [26] DT — Disable Dropping of TCP/IP Checksum Error Frames
  [25] RSF — Receive Store and Forward
  [21] TSF — Transmit Store and Forward
  [20] FTF — Flush Transmit FIFO
  [16:14] TTC — Transmit Threshold Control
    0=64; 1=128; 2=192; 3=256; 4=40; 5=32; 6=24; 7=16
  [13] ST — Start or Stop Transmission Command
  [12:11] RFD — Threshold for Deactivating Flow Control (in half-duplex and full-duplex)
    {v}=Full minus {v+1} KB, that is, FULL - {v+1} KB (v=0..3)
  [10:9] RFA — Threshold for Activating Flow Control (in half-duplex and full-duplex)
    0=Full minus 1 KB, that is, FULL - 1 KB; 1=Full minus 2 KB, that is, FULL - 2 KB; 2=Full minus 3 KB, that is, FULL - 3 KB
  [8] EFC — Enable HW Flow Control
  [7] FEF — Forward Error Frames
  [6] FUF — Forward Undersized Good Frames
  [5] DGF — Drop Giant Frames
  [4:3] RTC — Receive Threshold Control
    0=64; 1=32; 2=96; 3=128
  [2] OSF — Operate on Second Frame
  [1] SR — Start or Stop Receive
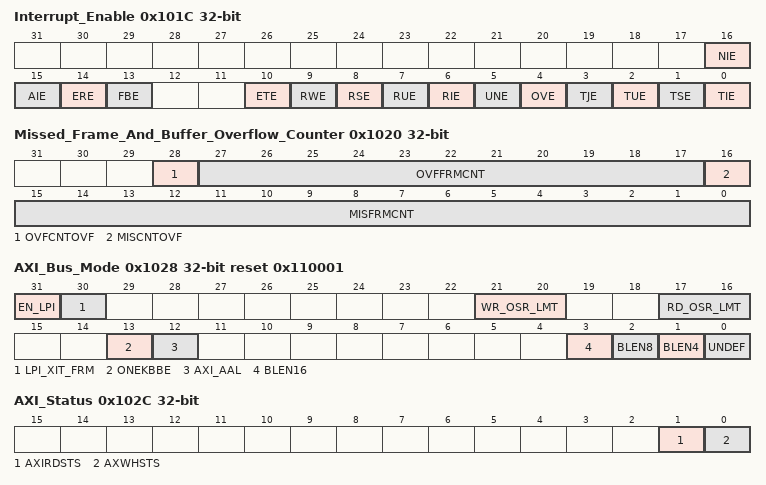
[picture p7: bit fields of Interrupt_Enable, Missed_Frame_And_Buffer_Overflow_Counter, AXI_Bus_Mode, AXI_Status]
0x101C Interrupt_Enable
  [16] NIE — Normal Interrupt Summary Enable
  [15] AIE — Abnormal Interrupt Summary Enable
  [14] ERE — Early Receive Interrupt Enable
  [13] FBE — Fatal Bus Error Enable
  [10] ETE — Early Transmit Interrupt Enable
  [9] RWE — Receive Watchdog Timeout Enable
  [8] RSE — Receive Stopped Enable
  [7] RUE — Receive Buffer Unavailable Enable
  [6] RIE — Receive Interrupt Enable
  [5] UNE — Underflow Interrupt Enable
  [4] OVE — Overflow Interrupt Enable
  [3] TJE — Transmit Jabber Timeout Enable
  [2] TUE — Transmit Buffer Unavailable Enable
  [1] TSE — Transmit Stopped Enable
  [0] TIE — Transmit Interrupt Enable
0x1020 Missed_Frame_And_Buffer_Overflow_Counter ro
  [28] OVFCNTOVF — Overflow Bit for FIFO Overflow Counter
  [27:17] OVFFRMCNT — Overflow Frame Counter
  [16] MISCNTOVF — Overflow Bit for Missed Frame Counter
  [15:0] MISFRMCNT — Missed Frame Counter
0x1024 Receive_Interrupt_Watchdog_Timer
  [7:0] RIWT — RI Watchdog Timer Count
0x1028 AXI_Bus_Mode reset 0x110001
  [31] EN_LPI — Enable Low Power Interface (LPI)
  [30] LPI_XIT_FRM — Unlock on Magic Packet or Remote Wake-Up Frame
  [21:20] WR_OSR_LMT — AXI Maximum Write OutStanding Request Limit
  [17:16] RD_OSR_LMT — AXI Maximum Read OutStanding Request Limit
  [13] ONEKBBE — 1 KB Boundary Crossing Enable for the GMAC-AXI Master
  [12] AXI_AAL ro — Address-Aligned Beats
  [3] BLEN16 — AXI Burst Length 16
  [2] BLEN8 — AXI Burst Length 8
  [1] BLEN4 — AXI Burst Length 4
  [0] UNDEF ro — AXI Undefined Burst Length
0x102C AXI_Status ro
  [1] AXIRDSTS — AXI Master Read Channel Status
  [0] AXWHSTS — AXI Master Write Channel
0x1048 Current_Host_Transmit_Descriptor ro
  [31:0] CURTDESAPTR — Host Transmit Descriptor Address Pointer
0x104C Current_Host_Receive_Descriptor ro
  [31:0] CURRDESAPTR — Host Receive Descriptor Address Pointer
0x1050 Current_Host_Transmit_Buffer_Address ro
  [31:0] CURTBUFAPTR — Host Transmit Buffer Address Pointer
0x1054 Current_Host_Receive_Buffer_Address ro
  [31:0] CURRBUFAPTR — Host Receive Buffer Address Pointer
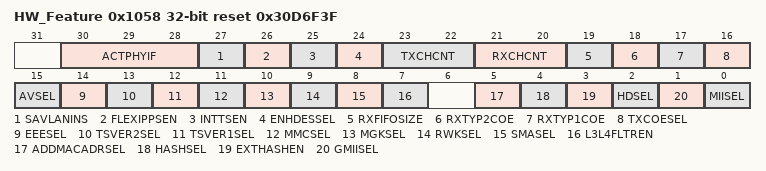
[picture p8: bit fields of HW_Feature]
0x1058 HW_Feature ro reset 0x30D6F3F
  [30:28] ACTPHYIF — Active or Selected PHY interface
    0=GMII or MII; other=Others (Reserved)
  [27] SAVLANINS — Source Address or VLAN Insertion
  [26] FLEXIPPSEN — Flexible Pulse-Per-Second Output (GMAC: 0)
  [25] INTTSEN — Timestamping with Internal System Time
  [24] ENHDESSEL — Enhanced Descriptor
  [23:22] TXCHCNT — Number of additional TX channels
  [21:20] RXCHCNT — Number of additional RX channels
  [19] RXFIFOSIZE — RX FIFO > 2,048 Bytes
  [18] RXTYP2COE — IP Checksum Offload (Type 2) in RX
  [17] RXTYP1COE — IP Checksum Offload (Type 1) in RX
  [16] TXCOESEL — Checksum Offload in TX
  [15] AVSEL — AV Feature
  [14] EEESEL — Energy Efficient Ethernet
  [13] TSVER2SEL — IEEE 1588-2008 Advanced Timestamp
  [12] TSVER1SEL — Only IEEE 1588-2002 Timestamp
  [11] MMCSEL — RMON Module
  [10] MGKSEL — PMT Magic Packet
  [9] RWKSEL — PMT Remote wakeup
  [8] SMASEL — SMA (MDIO) Interface
  [7] L3L4FLTREN — Layer 3 and Layer 4 Filter Feature
  [5] ADDMACADRSEL — Multiple MAC Address Registers
  [4] HASHSEL — HASH Filter
  [3] EXTHASHEN — Expanded DA Hash Filter
  [2] HDSEL — Half-Duplex support
  [1] GMIISEL — 1000 Mbps support
  [0] MIISEL — 10 or 100 Mbps support
